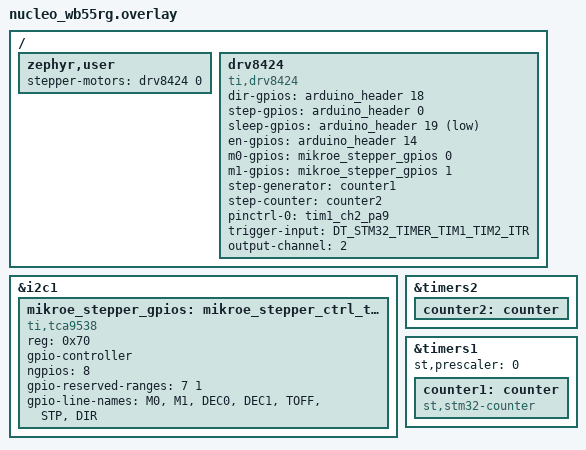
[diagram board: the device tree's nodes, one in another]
/*
 * Copyright (c) 2025 Navimatix GmbH
 * SPDX-License-Identifier: Apache-2.0
 */

#include <zephyr/dt-bindings/gpio/gpio.h>
#include <zephyr/dt-bindings/timer/stm32-timer-wb.h>

microbus_i2c: &i2c1 {};

/ {
	zephyr,user {
		stepper-motors = <&drv8424 0>;
	};
};

&i2c1 {
	status = "okay";

	mikroe_stepper_gpios: mikroe_stepper_ctrl_tca9538a@70 {
		status = "okay";
		compatible = "ti,tca9538";

		reg = <0x70>;

		gpio-controller;
		ngpios = <8>;
		#gpio-cells = <2>;

		gpio-reserved-ranges = <7 1>;

		gpio-line-names =
			"M0",
			"M1",
			"DEC0",
			"DEC1",
			"TOFF",
			"STP",
			"DIR";
	};
};

/ {
	drv8424: drv8424 {
		status = "okay";
		compatible = "ti,drv8424";

		dir-gpios = <&arduino_header 18 0>; /* D12 */
		step-gpios = <&arduino_header 0 0>; /* A0 */
		sleep-gpios = <&arduino_header 19 GPIO_ACTIVE_LOW>; /* D13 */
		en-gpios  = <&arduino_header 14 0>; /* D8 */
		m0-gpios = <&mikroe_stepper_gpios 0 0>;
		m1-gpios = <&mikroe_stepper_gpios 1 0>;
		step-generator = <&counter1>;
		step-counter = <&counter2>;
		pinctrl-0 = < &tim1_ch2_pa9 >;
		pinctrl-names = "default";
		trigger-input = <DT_STM32_TIMER_TIM1_TIM2_ITR>;
		output-channel = <2>;

		#address-cells = <1>;
		#size-cells = <0>;
		#stepper-motor-cells = <0>;
	};
};

&timers2 {
	status = "okay";
	counter2: counter {
		status = "okay";
	};
};

&timers1 {
	status = "okay";
	st,prescaler = < 0 >;
	counter1: counter {
		status = "okay";
		compatible = "st,stm32-counter";
	};
};
